# GD32H75E register map
File version: 1.0
CPU: CM7 r1p2, little endian, MPU, FPU, 4 interrupt priority bits
Registers are 32-bit, read-write, reset 0x0 unless marked. A register's access mark holds for its fields unless they carry their own. Offsets are from the block's base; [hi:lo] are bit positions; {n}, {i} and the like mark numbered series; 'fields as' and 'values as' point back to an identical list.

## EDOUT — En-coder Divided-Output controller
Base 0x40018800
0x00 CTL — Control register
  [0] POL — The active polarity of the B-phase output signal selection
0x04 ENABLE
  [0] EDOUTEN — EDOUT enable bit
0x08 LOC — Location register
  [15:0] LOCMAX — This bits set the maximum location value for one rotation
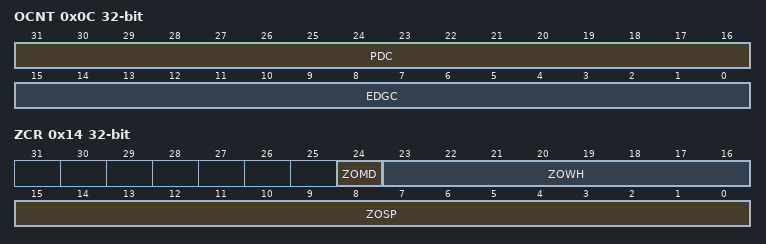
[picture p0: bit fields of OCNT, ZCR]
0x0C OCNT — Output counter register
  [31:16] PDC — These bits set the phase difference between the A-phase signal and the B-phase signal for the next carrier cycle
  [15:0] EDGC — These bits set the number of edges of the A-phase signal and the B-phase signal for the next carrier cycle
0x10 LCNT — Location counter register
  [15:0] LOCCNT — These bits are used to set the current position value
0x14 ZCR — Z-PHASE configure register
  [24] ZOMD — Z-PHASE output mode
  [23:16] ZOWH — Z-PHASE output width
  [15:0] ZOSP — Z-PHASE output start position

## FAC — Filter arithmetic accelerator
Base 0x48024800
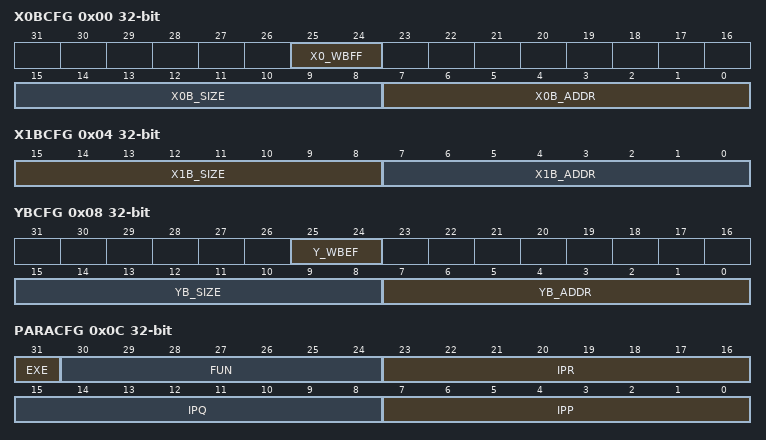
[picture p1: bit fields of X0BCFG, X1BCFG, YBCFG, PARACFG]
0x00 X0BCFG — FAC X0 buffer configure register
  [25:24] X0_WBFF — Buffer full flag of watermark
  [15:8] X0B_SIZE — X0 buffer size, the number of feed-forward taps
  [7:0] X0B_ADDR — X0 buffer base address
0x04 X1BCFG — FAC X1 buffer configure register
  [15:8] X1B_SIZE — X1 buffer size
  [7:0] X1B_ADDR — X1 buffer base address
0x08 YBCFG — FAC Y buffer configure register
  [25:24] Y_WBEF — Buffer empty flag of watermark
  [15:8] YB_SIZE — Y buffer size
  [7:0] YB_ADDR — Y buffer base address
0x0C PARACFG — FAC Parameter configure register
  [31] EXE — Execution
  [30:24] FUN — Function
  [23:16] IPR — Input parameter IPR
  [15:8] IPQ — Input parameter IPQ
  [7:0] IPP — Input parameter IPP
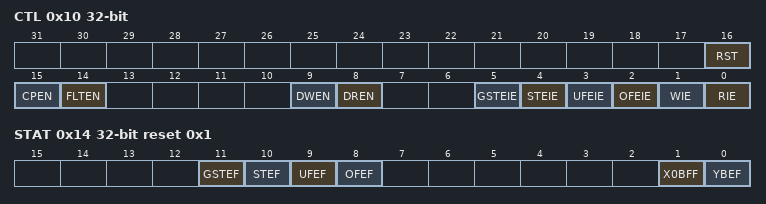
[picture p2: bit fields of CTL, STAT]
0x10 CTL — FAC Control register
  [16] RST — Reset FAC unit
  [15] CPEN — Clipping enable
  [14] FLTEN — Floating point format enable
  [9] DWEN — DMA write channel enable
  [8] DREN — DMA read channel enable
  [5] GSTEIE — Gain saturation error interrupt enable
  [4] STEIE — Saturation error interrupt enable
  [3] UFEIE — Underflow error interrupt enable
  [2] OFEIE — Overflow error interrupt enable
  [1] WIE — Write interrupt enable
  [0] RIE — Read interrupt enable
0x14 STAT ro reset 0x1 — FAC Status register
  [11] GSTEF — Gain saturation error flag, it is set when gain exceed range
  [10] STEF — Saturation error flag
  [9] UFEF — Underflow error flag
  [8] OFEF — Overflow error flag
  [1] X0BFF — X0 buffer full flag
  [0] YBEF — Y buffer empty flag
0x18 WDATA — FAC write data register
  [31:0] WDATA — Write data
0x1C RDATA — FAC read data register
  [31:0] RDATA — Read data

## FWDGT — free watchdog timer
Base 0x58004800
0x00 CTL wo — Control register
  [15:0] CMD — Key value
0x04 PSC — Prescaler register
  [2:0] PSC — Prescaler divider
0x08 RLD reset 0xFFF — Reload register
  [11:0] RLD — Watchdog counter reload value
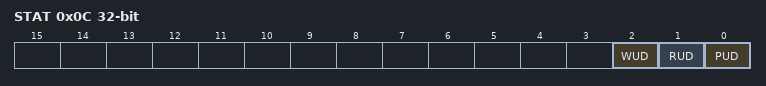
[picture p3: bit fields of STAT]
0x0C STAT ro — Status register
  [2] WUD — Watchdog counter window value update
  [1] RUD — Watchdog counter reload value update
  [0] PUD — Watchdog prescaler value update
0x10 WND reset 0xFFF — Window register
  [11:0] WND — Watchdog counter window value

## GPIOA — General-purpose I/Os
Base 0x58020000
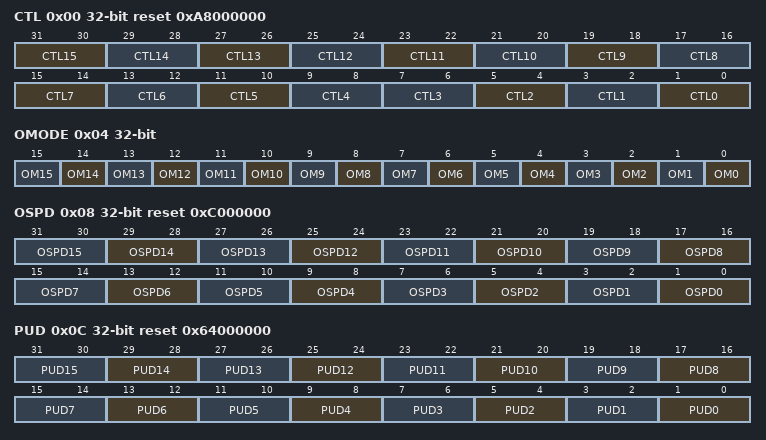
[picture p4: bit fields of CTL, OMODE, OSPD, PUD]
0x00 CTL reset 0xA8000000 — GPIO port control register
  [2n+1:2n] CTL{n} (n=7..15) — Port x configuration bits (x = {n})
  [13:12] CTL6 — Port x configuration bits (x = 6 )
  [11:10] CTL5 — Port x configuration bits (x = 5)
  [9:8] CTL4 — Port x configuration bits (x = 4 )
  [2n+1:2n] CTL{n} (n=0..3) — Port x configuration bits (x = {n})
0x04 OMODE — GPIO port output mode register
  [n] OM{n} (n=0..15) — Port {n} output mode bit
0x08 OSPD reset 0xC000000 — GPIO port output speed register
  [2n+1:2n] OSPD{n} (n=0..15) — Port {n} output max speed bits
0x0C PUD reset 0x64000000 — GPIO port pull-up/pull-down register
  [2n+1:2n] PUD{n} (n=0..15) — Port {n} pull-up or pull-down bits
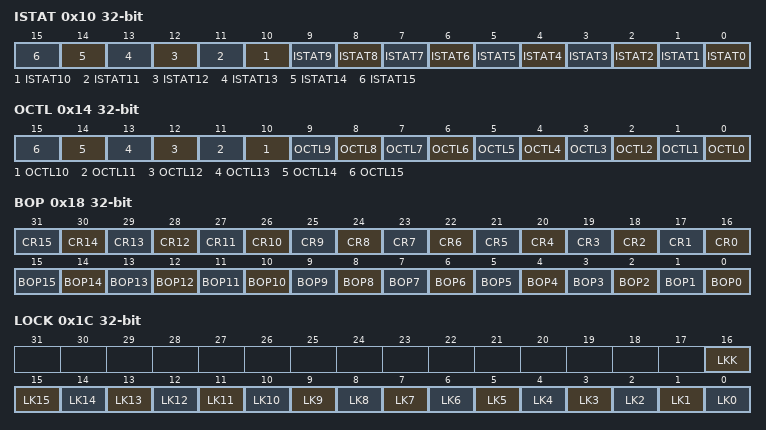
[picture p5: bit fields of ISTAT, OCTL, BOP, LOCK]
0x10 ISTAT ro — GPIO port input status register
  [n] ISTAT{n} (n=0..15) — Port input status (y = {n})
0x14 OCTL — GPIO port output control register
  [n] OCTL{n} (n=0..15) — Port output control (y = {n})
0x18 BOP wo — GPIO port bit operate register
  [n+16] CR{n} (n=0..15) — Port Clear bit {n}
  [n] BOP{n} (n=0..15) — Port Set bit {n}
0x1C LOCK — GPIO port configuration lock register
  [16] LKK — Lock sequence key
  [n] LK{n} (n=0..15) — Port Lock bit {n}
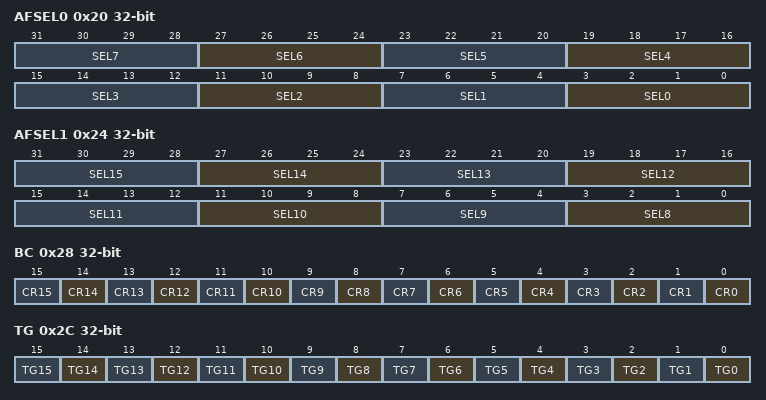
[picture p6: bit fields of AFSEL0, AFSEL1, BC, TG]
0x20 AFSEL0 — GPIO alternate function selected register 0
  [4n+3:4n] SEL{n} (n=0..7) — Port {n} alternate function selected
0x24 AFSEL1 — GPIO alternate function selected register 1
  [4n-29:4n-32] SEL{n} (n=8..15) — Port {n} alternate function selected
0x28 BC wo — Bit clear register
  [n] CR{n} (n=0..15) — Port cleat bit
0x2C TG wo — Port bit toggle register
  [n] TG{n} (n=0..15) — Port toggle bit
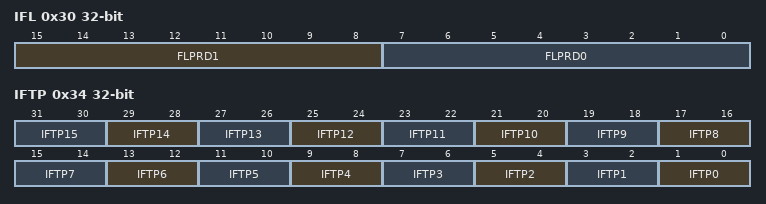
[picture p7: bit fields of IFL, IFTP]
0x30 IFL — Input filtering regist
  [15:8] FLPRD1 — Filter sampling period for GPIO8 to GPIO15:
  [7:0] FLPRD0 — Filter sampling period for GPIO1 to GPIO7:
0x34 IFTP — Input filtering type regist
  [2n+1:2n] IFTP{n} (n=0..15) — Pin {n} input filtering type bits

## GPIOB — General-purpose I/Os
Base 0x58020400
Registers as GPIOA; these are added or differ:
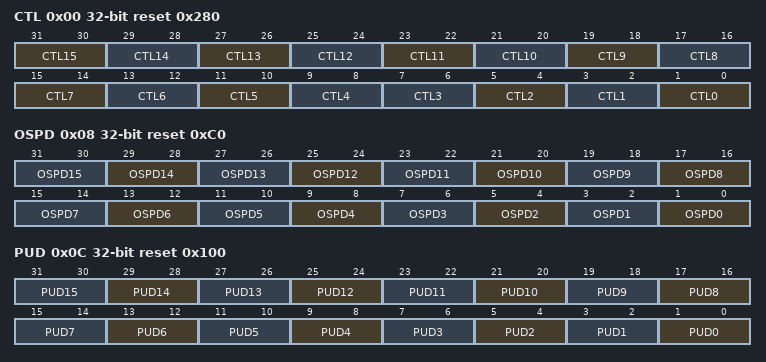
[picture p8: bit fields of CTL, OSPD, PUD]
0x00 CTL reset 0x280 — GPIO port control register
  fields as GPIOA.CTL
0x08 OSPD reset 0xC0 — GPIO port output speed register
  [2n+1:2n] OSPD{n} (n=0..15) — Port {n} output max speed bits
0x0C PUD reset 0x100 — GPIO port pull-up/pull-down register
  [2n+1:2n] PUD{n} (n=0..15) — Port {n} pull-up or pull-down bits

## GPIOC — General-purpose I/Os
Base 0x58020800
Same registers: GPIOD 0x58020C00, GPIOE 0x58021000, GPIOF 0x58021400, GPIOG 0x58021800, GPIOH 0x58021C00
Registers as GPIOA; these are added or differ:
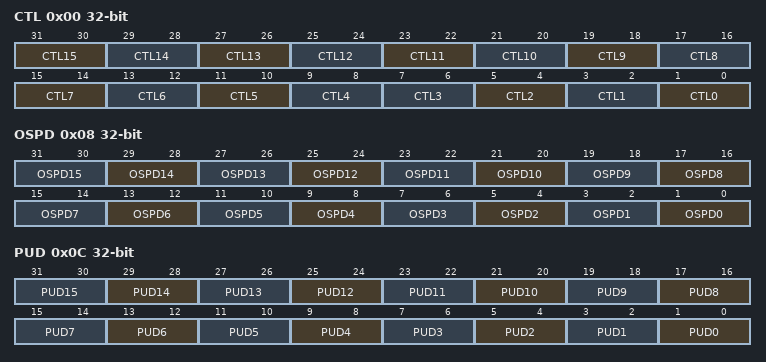
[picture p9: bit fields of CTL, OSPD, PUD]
0x00 CTL — GPIO port control register
  fields as GPIOA.CTL
0x08 OSPD — GPIO port output speed register
  [2n+1:2n] OSPD{n} (n=0..15) — Port {n} output max speed bits
0x0C PUD — GPIO port pull-up/pull-down register
  [2n+1:2n] PUD{n} (n=0..15) — Port {n} pull-up or pull-down bits
